# STM32G431xx register map
File version: 1.9
CPU: CM4 r0p1, little endian, MPU, FPU, 4 interrupt priority bits
Registers are 32-bit, read-write, reset 0x0 unless marked. A register's access mark holds for its fields unless they carry their own. Offsets are from the block's base; [hi:lo] are bit positions; {n}, {i} and the like mark numbered series.

## RCC (part 2 of 2) — Reset and clock control
Base 0x40021000
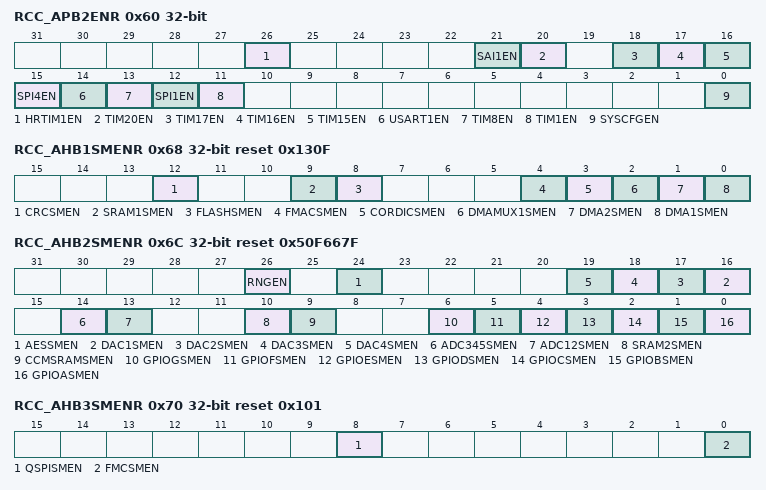
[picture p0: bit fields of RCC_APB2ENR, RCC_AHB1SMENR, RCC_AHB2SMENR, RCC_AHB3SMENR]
0x60 RCC_APB2ENR — APB2 peripheral clock enable register
  [26] HRTIM1EN — HRTIM1 clock enable Set and cleared by software.
    0=HRTIM1 clock disabled; 1=HRTIM1 clock enable
  [21] SAI1EN — SAI1 clock enable Set and cleared by software.
    0=SAI1 clock disabled; 1=SAI1 clock enabled
  [20] TIM20EN — TIM20 timer clock enable Set and cleared by software.
    0=TIM20 clock disabled; 1=TIM20 clock enabled
  [18] TIM17EN — TIM17 timer clock enable Set and cleared by software.
    0=TIM17 timer clock disabled; 1=TIM17 timer clock enabled
  [17] TIM16EN — TIM16 timer clock enable Set and cleared by software.
    0=TIM16 timer clock disabled; 1=TIM16 timer clock enabled
  [16] TIM15EN — TIM15 timer clock enable Set and cleared by software.
    0=TIM15 timer clock disabled; 1=TIM15 timer clock enabled
  [15] SPI4EN — SPI4 clock enable Set and cleared by software.
    0=SPI4 clock disabled; 1=SPI4 clock enabled
  [14] USART1EN — USART1clock enable Set and cleared by software.
    0=USART1clock disabled; 1=USART1clock enabled
  [13] TIM8EN — TIM8 timer clock enable Set and cleared by software.
    0=TIM8 timer clock disabled; 1=TIM8 timer clock enabled
  [12] SPI1EN — SPI1 clock enable Set and cleared by software.
    0=SPI1 clock disabled; 1=SPI1 clock enabled
  [11] TIM1EN — TIM1 timer clock enable Set and cleared by software.
    0=TIM1 timer clock disabled; 1=TIM1P timer clock enabled
  [0] SYSCFGEN — SYSCFG + COMP + VREFBUF + OPAMP clock enable Set and cleared by software.
    0=SYSCFG + COMP + VREFBUF + OPAMP clock disabled; 1=SYSCFG + COMP + VREFBUF + OPAMP clock enabled
0x68 RCC_AHB1SMENR reset 0x130F — AHB1 peripheral clocks enable in Sleep and Stop modes register
  [12] CRCSMEN — CRC clocks enable during Sleep and Stop modes Set and cleared by software.
    0=CRC clocks disabled by the clock gating during Sleep and Stop modes; 1=CRC clocks enabled by the clock gating<sup>(1)</sup> during Sleep and Stop modes
  [9] SRAM1SMEN — SRAM1 interface clocks enable during Sleep and Stop modes Set and cleared by software.
    0=SRAM1 interface clocks disabled by the clock gating<sup>(1)</sup> during Sleep and Stop modes; 1=SRAM1 interface clocks enabled by the clock gating<sup>(1)</sup> during Sleep and Stop modes
  [8] FLASHSMEN — Flash memory interface clocks enable during Sleep and Stop modes Set and cleared by software.
    0=Flash memory interface clocks disabled by the clock gating<sup>(1)</sup> during Sleep and Stop modes; 1=Flash memory interface clocks enabled by the clock gating<sup>(1)</sup> during Sleep and Stop modes
  [4] FMACSMEN — FMACSM clock enable. Set and cleared by software.
    0=FMACSM clocks disabled by the clock gating<sup>(1)</sup> during Sleep and Stop modes; 1=FMACSM clocks enabled by the clock gating<sup>(1)</sup> during Sleep and Stop modes
  [3] CORDICSMEN — CORDICSM clock enable. Set and cleared by software.
    0=CORDICSM clocks disabled; 1=CORDICSM clocks enabled
  [2] DMAMUX1SMEN — DMAMUX1 clock enable during Sleep and Stop modes. Set and cleared by software.
    0=DMAMUX1 clocks disabled by the clock gating<sup>(1)</sup> during Sleep and Stop modes; 1=DMAMUX1 clocks enabled by the clock gating<sup>(1)</sup> during Sleep and Stop modes
  [1] DMA2SMEN — DMA2 clocks enable during Sleep and Stop modes Set and cleared by software during Sleep mode.
    0=DMA2 clocks disabled by the clock gating<sup>(1)</sup> during Sleep and Stop modes; 1=DMA2 clocks enabled by the clock gating<sup>(1)</sup> during Sleep and Stop modes
  [0] DMA1SMEN — DMA1 clocks enable during Sleep and Stop modes Set and cleared by software.
    0=DMA1 clocks disabled by the clock gating<sup>(1)</sup> during Sleep and Stop modes; 1=DMA1 clocks enabled by the clock gating<sup>(1)</sup> during Sleep and Stop modes
0x6C RCC_AHB2SMENR reset 0x50F667F — AHB2 peripheral clocks enable in Sleep and Stop modes register
  [26] RNGEN — RNG enable Set and cleared by software.
    0=RNG disabled; 1=RNG enabled
  [24] AESSMEN — AESM clocks enable Set and cleared by software.
    0=AESM clocks disabled; 1=AESM clocks enabled
  [n+15] DAC{n}SMEN (n=1..4) — DAC{n} clock enable Set and cleared by software.
    0=DAC{n} clock disabled; 1=DAC{n} clock enabled during sleep and stop modes
  [14] ADC345SMEN — ADC345 clock enable Set and cleared by software.
    0=ADC345 clock disabled; 1=ADC345 clock enabled
  [13] ADC12SMEN — ADC12 clocks enable during Sleep and Stop modes Set and cleared by software.
    0=ADC12 clocks disabled by the clock gating during Sleep and Stop modes; 1=ADC12 clocks enabled by the clock gating<sup>(1)</sup> during Sleep and Stop modes
  [10] SRAM2SMEN — SRAM2 interface clocks enable during Sleep and Stop modes Set and cleared by software.
    0=SRAM2 interface clocks disabled by the clock gating<sup>(1)</sup> during Sleep and Stop modes; 1=SRAM2 interface clocks enabled by the clock gating<sup>(1)</sup> during Sleep and Stop modes
  [9] CCMSRAMSMEN — CCM SRAM interface clocks enable during Sleep and Stop modes Set and cleared by software.
    0=CCM SRAM interface clocks disabled by the clock gating<sup>(1)</sup> during Sleep and Stop modes; 1=CCM SRAM interface clocks enabled by the clock gating<sup>(1)</sup> during Sleep and Stop modes
  [6] GPIOGSMEN — IO port G clocks enable during Sleep and Stop modes Set and cleared by software.
    0=IO port G clocks disabled by the clock gating<sup>(1)</sup> during Sleep and Stop modes; 1=IO port G clocks enabled by the clock gating<sup>(1)</sup> during Sleep and Stop modes
  [5] GPIOFSMEN — IO port F clocks enable during Sleep and Stop modes Set and cleared by software.
    0=IO port F clocks disabled by the clock gating<sup>(1)</sup> during Sleep and Stop modes; 1=IO port F clocks enabled by the clock gating<sup>(1)</sup> during Sleep and Stop modes
  [4] GPIOESMEN — IO port E clocks enable during Sleep and Stop modes Set and cleared by software.
    0=IO port E clocks disabled by the clock gating<sup>(1)</sup> during Sleep and Stop modes; 1=IO port E clocks enabled by the clock gating<sup>(1)</sup> during Sleep and Stop modes
  [3] GPIODSMEN — IO port D clocks enable during Sleep and Stop modes Set and cleared by software.
    0=IO port D clocks disabled by the clock gating<sup>(1)</sup> during Sleep and Stop modes; 1=IO port D clocks enabled by the clock gating<sup>(1)</sup> during Sleep and Stop modes
  [2] GPIOCSMEN — IO port C clocks enable during Sleep and Stop modes Set and cleared by software.
    0=IO port C clocks disabled by the clock gating<sup>(1)</sup> during Sleep and Stop modes; 1=IO port C clocks enabled by the clock gating<sup>(1)</sup> during Sleep and Stop modes
  [1] GPIOBSMEN — IO port B clocks enable during Sleep and Stop modes Set and cleared by software.
    0=IO port B clocks disabled by the clock gating<sup>(1)</sup> during Sleep and Stop modes; 1=IO port B clocks enabled by the clock gating<sup>(1)</sup> during Sleep and Stop modes
  [0] GPIOASMEN — IO port A clocks enable during Sleep and Stop modes Set and cleared by software.
    0=IO port A clocks disabled by the clock gating<sup>(1)</sup> during Sleep and Stop modes; 1=IO port A clocks enabled by the clock gating<sup>(1)</sup> during Sleep and Stop modes
0x70 RCC_AHB3SMENR reset 0x101 — AHB3 peripheral clocks enable in Sleep and Stop modes register
  [8] QSPISMEN — QUADSPI memory interface clock enable during Sleep and Stop modes Set and cleared by software.
    0=QUADSPI clock disabled by the clock gating during Sleep and Stop modes; 1=QUADSPI clock enabled by the clock gating<sup>(1)</sup> during Sleep and Stop modes
  [0] FMCSMEN — Flexible static memory controller clocks enable during Sleep and Stop modes Set and cleared by software.
    0=FSMC clocks disabled by the clock gating<sup>(1)</sup> during Sleep and Stop modes; 1=FSMC clocks enabled by the clock gating<sup>(1)</sup> during Sleep and Stop modes
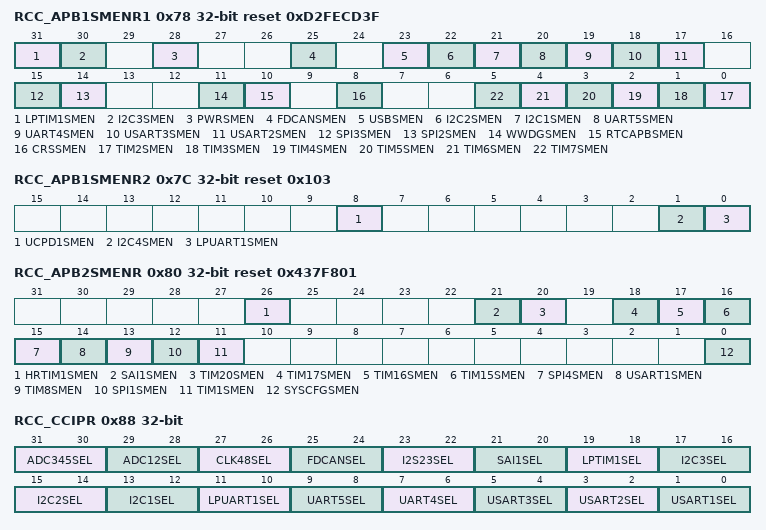
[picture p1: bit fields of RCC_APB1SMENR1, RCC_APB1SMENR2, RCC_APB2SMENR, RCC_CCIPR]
0x78 RCC_APB1SMENR1 reset 0xD2FECD3F — APB1 peripheral clocks enable in Sleep and Stop modes register 1
  [31] LPTIM1SMEN — Low power timer 1 clocks enable during Sleep and Stop modes Set and cleared by software.
    0=LPTIM1 clocks disabled by the clock gating during Sleep and Stop modes; 1=LPTIM1 clocks enabled by the clock gating<sup>(1)</sup> during Sleep and Stop modes
  [30] I2C3SMEN — I2C3 clocks enable during Sleep and Stop modes Set and cleared by software.
    0=I2C3 clocks disabled by the clock gating<sup>(1)</sup> during Sleep and Stop modes; 1=I2C3 clocks enabled by the clock gating<sup>(1)</sup> during Sleep and Stop modes
  [28] PWRSMEN — Power interface clocks enable during Sleep and Stop modes Set and cleared by software.
    0=Power interface clocks disabled by the clock gating<sup>(1)</sup> during Sleep and Stop modes; 1=Power interface clocks enabled by the clock gating<sup>(1)</sup> during Sleep and Stop modes
  [25] FDCANSMEN — FDCAN clocks enable during Sleep and Stop modes Set and cleared by software.
    0=FDCAN clocks disabled by the clock gating<sup>(1)</sup> during Sleep and Stop modes; 1=FDCAN clocks enabled by the clock gating<sup>(1)</sup> during Sleep and Stop modes
  [23] USBSMEN — USB device clocks enable during Sleep and Stop modes Set and cleared by software.
    0=USB device clocks disabled by the clock gating<sup>(1)</sup> during Sleep and Stop modes; 1=USB device clocks enabled by the clock gating<sup>(1)</sup> during Sleep and Stop modes
  [22] I2C2SMEN — I2C2 clocks enable during Sleep and Stop modes Set and cleared by software.
    0=I2C2 clocks disabled by the clock gating<sup>(1)</sup> during Sleep and Stop modes; 1=I2C2 clocks enabled by the clock gating<sup>(1)</sup> during Sleep and Stop modes
  [21] I2C1SMEN — I2C1 clocks enable during Sleep and Stop modes Set and cleared by software.
    0=I2C1 clocks disabled by the clock gating<sup>(1)</sup> during Sleep and Stop modes; 1=I2C1 clocks enabled by the clock gating<sup>(1)</sup> during Sleep and Stop modes
  [20] UART5SMEN — UART5 clocks enable during Sleep and Stop modes Set and cleared by software.
    0=UART5 clocks disabled by the clock gating<sup>(1)</sup> during Sleep and Stop modes; 1=UART5 clocks enabled by the clock gating<sup>(1)</sup> during Sleep and Stop modes
  [19] UART4SMEN — UART4 clocks enable during Sleep and Stop modes Set and cleared by software.
    0=UART4 clocks disabled by the clock gating<sup>(1)</sup> during Sleep and Stop modes; 1=UART4 clocks enabled by the clock gating<sup>(1)</sup> during Sleep and Stop modes
  [18] USART3SMEN — USART3 clocks enable during Sleep and Stop modes Set and cleared by software.
    0=USART3 clocks disabled by the clock gating<sup>(1)</sup> during Sleep and Stop modes; 1=USART3 clocks enabled by the clock gating<sup>(1)</sup> during Sleep and Stop modes
  [17] USART2SMEN — USART2 clocks enable during Sleep and Stop modes Set and cleared by software.
    0=USART2 clocks disabled by the clock gating<sup>(1)</sup> during Sleep and Stop modes; 1=USART2 clocks enabled by the clock gating<sup>(1)</sup> during Sleep and Stop modes
  [15] SPI3SMEN — SPI3 clocks enable during Sleep and Stop modes Set and cleared by software.
    0=SPI3 clocks disabled by the clock gating<sup>(1)</sup> during Sleep and Stop modes; 1=SPI3 clocks enabled by the clock gating<sup>(1)</sup> during Sleep and Stop modes
  [14] SPI2SMEN — SPI2 clocks enable during Sleep and Stop modes Set and cleared by software.
    0=SPI2 clocks disabled by the clock gating<sup>(1)</sup> during Sleep and Stop modes; 1=SPI2 clocks enabled by the clock gating<sup>(1)</sup> during Sleep and Stop modes
  [11] WWDGSMEN — Window watchdog clocks enable during Sleep and Stop modes Set and cleared by software. This bit is forced to ‘1’ by hardware when the hardware WWDG option is activated.
    0=Window watchdog clocks disabled by the clock gating<sup>(1)</sup> during Sleep and Stop modes; 1=Window watchdog clocks enabled by the clock gating<sup>(1)</sup> during Sleep and Stop modes
  [10] RTCAPBSMEN — RTC APB clock enable during Sleep and Stop modes Set and cleared by software
    0=RTC APB clock disabled by the clock gating<sup>(1)</sup> during Sleep and Stop modes; 1=RTC APB clock enabled by the clock gating<sup>(1)</sup> during Sleep and Stop modes
  [8] CRSSMEN — CRS timer clocks enable during Sleep and Stop modes Set and cleared by software.
    0=CRS clocks disabled by the clock gating<sup>(1)</sup> during Sleep and Stop modes; 1=CRS clocks enabled by the clock gating<sup>(1)</sup> during Sleep and Stop modes
  [n-2] TIM{n}SMEN (n=2..7) — TIM{n} timer clocks enable during Sleep and Stop modes Set and cleared by software.
    0=TIM{n} clocks disabled by the clock gating<sup>(1)</sup> during Sleep and Stop modes; 1=TIM{n} clocks enabled by the clock gating<sup>(1)</sup> during Sleep and Stop modes
0x7C RCC_APB1SMENR2 reset 0x103 — APB1 peripheral clocks enable in Sleep and Stop modes register 2
  [8] UCPD1SMEN — UCPD1 clocks enable during Sleep and Stop modes Set and cleared by software.
    0=UCPD1 clocks disabled by the clock gating during Sleep and Stop modes; 1=UCPD1 clocks enabled by the clock gating<sup>(1)</sup> during Sleep and Stop modes
  [1] I2C4SMEN — I2C4 clocks enable during Sleep and Stop modes Set and cleared by software
    0=I2C4 clocks disabled by the clock gating during Sleep and Stop modes; 1=I2C4 clock enabled by the clock gating<sup>(1)</sup> during Sleep and Stop modes
  [0] LPUART1SMEN — Low power UART 1 clocks enable during Sleep and Stop modes Set and cleared by software.
    0=LPUART1 clocks disabled by the clock gating<sup>(1)</sup> during Sleep and Stop modes; 1=LPUART1 clocks enabled by the clock gating<sup>(1)</sup> during Sleep and Stop modes
0x80 RCC_APB2SMENR reset 0x437F801 — APB2 peripheral clocks enable in Sleep and Stop modes register
  [26] HRTIM1SMEN — HRTIM1 timer clocks enable during Sleep and Stop modes Set and cleared by software.
    0=HRTIM1 clocks disabled by the clock gating<sup>(1)</sup> during Sleep and Stop modes; 1=HRTIM1 clocks enabled by the clock gating<sup>(1)</sup> during Sleep and Stop modes
  [21] SAI1SMEN — SAI1 clocks enable during Sleep and Stop modes Set and cleared by software.
    0=SAI1 clocks disabled by the clock gating<sup>(1)</sup> during Sleep and Stop modes; 1=SAI1 clocks enabled by the clock gating<sup>(1)</sup> during Sleep and Stop modes
  [20] TIM20SMEN — TIM20 timer clocks enable during Sleep and Stop modes Set and cleared by software.
    0=TIM20 clocks disabled by the clock gating<sup>(1)</sup> during Sleep and Stop modes; 1=TIM20 clocks enabled by the clock gating<sup>(1)</sup> during Sleep and Stop modes
  [18] TIM17SMEN — TIM17 timer clocks enable during Sleep and Stop modes Set and cleared by software.
    0=TIM17 timer clocks disabled by the clock gating<sup>(1)</sup> during Sleep and Stop modes; 1=TIM17 timer clocks enabled by the clock gating<sup>(1)</sup> during Sleep and Stop modes
  [17] TIM16SMEN — TIM16 timer clocks enable during Sleep and Stop modes Set and cleared by software.
    0=TIM16 timer clocks disabled by the clock gating during Sleep and Stop modes; 1=TIM16 timer clocks enabled by the clock gating<sup>(1)</sup> during Sleep and Stop modes
  [16] TIM15SMEN — TIM15 timer clocks enable during Sleep and Stop modes Set and cleared by software.
    0=TIM15 timer clocks disabled by the clock gating<sup>(1)</sup> during Sleep and Stop modes; 1=TIM15 timer clocks enabled by the clock gating<sup>(1)</sup> during Sleep and Stop mode
  [15] SPI4SMEN — SPI4 timer clocks enable during Sleep and Stop modes Set and cleared by software.
    0=SPI4 clocks disabled by the clock gating<sup>(1)</sup> during Sleep and Stop modes; 1=SPI4 clocks enabled by the clock gating<sup>(1)</sup> during Sleep and Stop mode
  [14] USART1SMEN — USART1clocks enable during Sleep and Stop modes Set and cleared by software.
    0=USART1clocks disabled by the clock gating<sup>(1)</sup> during Sleep and Stop modes; 1=USART1clocks enabled by the clock gating<sup>(1)</sup> during Sleep and Stop modes
  [13] TIM8SMEN — TIM8 timer clocks enable during Sleep and Stop modes Set and cleared by software.
    0=TIM8 timer clocks disabled by the clock gating<sup>(1)</sup> during Sleep and Stop modes; 1=TIM8 timer clocks enabled by the clock gating<sup>(1)</sup> during Sleep and Stop modes
  [12] SPI1SMEN — SPI1 clocks enable during Sleep and Stop modes Set and cleared by software.
    0=SPI1 clocks disabled by the clock gating during<sup>(1)</sup> Sleep and Stop modes; 1=SPI1 clocks enabled by the clock gating during<sup>(1)</sup> Sleep and Stop modes
  [11] TIM1SMEN — TIM1 timer clocks enable during Sleep and Stop modes Set and cleared by software.
    0=TIM1 timer clocks disabled by the clock gating<sup>(1)</sup> during Sleep and Stop modes; 1=TIM1P timer clocks enabled by the clock gating<sup>(1)</sup> during Sleep and Stop modes
  [0] SYSCFGSMEN — SYSCFG + COMP + VREFBUF + OPAMP clocks enable during Sleep and Stop modes Set and cleared by software.
    0=SYSCFG + COMP + VREFBUF + OPAMP clocks disabled by the clock gating<sup>(1)</sup> during Sleep and Stop modes; 1=SYSCFG + COMP + VREFBUF + OPAMP clocks enabled by the clock gating<sup>(1)</sup> during Sleep and Stop modes
0x88 RCC_CCIPR — Peripherals independent clock configuration register
  [31:30] ADC345SEL — ADC3/4/5 clock source selection These bits are set and cleared by software to select the clock source used by the ADC345 interface.
    0=No clock selected; 1=PLL “P” clock selected as ADC345 clock; 2=System clock selected as ADC3/4/5 clock
  [29:28] ADC12SEL — ADC1/2 clock source selection These bits are set and cleared by software to select the clock source used by the ADC interface.
    0=No clock selected; 1=PLL “P” clock selected as ADC1/2 clock; 2=System clock selected as ADC1/2 clock
  [27:26] CLK48SEL — 48 MHz clock source selection These bits are set and cleared by software to select the 48 MHz clock source used by USB device FS and RNG.
    0=HSI48 clock selected as 48 MHz clock; 2=PLL “Q” clock (PLL48M1CLK) selected as 48 MHz clock; 3=Reserved, must be kept at reset value
  [25:24] FDCANSEL
  [23:22] I2S23SEL — clock source selection These bits are set and cleared by software to select the I2S23 clock source.
    0=System clock selected as I2S23 clock; 1=PLL “Q” clock selected as I2S23 clock; 2=Clock provided on I2S_CKIN pin is selected as I2S23 clock; 3=HSI16 clock selected as I2S23 clock
  [21:20] SAI1SEL — clock source selection These bits are set and cleared by software to select the SAI clock source.
    0=System clock selected as SAI clock; 1=PLL “Q” clock selected as SAI clock; 2=Clock provided on I2S_CKIN pin selected as SAI clock; 3=HSI16 clock selected as SAI clock
  [19:18] LPTIM1SEL — Low power timer 1 clock source selection These bits are set and cleared by software to select the LPTIM1 clock source.
    0=PCLK selected as LPTIM1 clock; 1=LSI clock selected as LPTIM1 clock; 2=HSI16 clock selected as LPTIM1 clock; 3=LSE clock selected as LPTIM1 clock
  [17:16] I2C3SEL — I2C3 clock source selection These bits are set and cleared by software to select the I2C3 clock source.
    0=PCLK selected as I2C3 clock; 1=System clock (SYSCLK) selected as I2C3 clock; 2=HSI16 clock selected as I2C3 clock
  [15:14] I2C2SEL — I2C2 clock source selection These bits are set and cleared by software to select the I2C2 clock source.
    0=PCLK selected as I2C2 clock; 1=System clock (SYSCLK) selected as I2C2 clock; 2=HSI16 clock selected as I2C2 clock
  [13:12] I2C1SEL — I2C1 clock source selection These bits are set and cleared by software to select the I2C1 clock source.
    0=PCLK selected as I2C1 clock; 1=System clock (SYSCLK) selected as I2C1 clock; 2=HSI16 clock selected as I2C1 clock
  [11:10] LPUART1SEL — LPUART1 clock source selection These bits are set and cleared by software to select the LPUART1 clock source.
    0=PCLK selected as LPUART1 clock; 1=System clock (SYSCLK) selected as LPUART1 clock; 2=HSI16 clock selected as LPUART1 clock; 3=LSE clock selected as LPUART1 clock
  [9:8] UART5SEL — UART5 clock source selection These bits are set and cleared by software to select the UART5 clock source.
    0=PCLK selected as UART5 clock; 1=System clock (SYSCLK) selected as UART5 clock; 2=HSI16 clock selected as UART5 clock; 3=LSE clock selected as UART5 clock
  [7:6] UART4SEL — UART4 clock source selection This bit is set and cleared by software to select the UART4 clock source.
    0=PCLK selected as UART4 clock; 1=System clock (SYSCLK) selected as UART4 clock; 2=HSI16 clock selected as UART4 clock; 3=LSE clock selected as UART4 clock
  [5:4] USART3SEL — USART3 clock source selection This bit is set and cleared by software to select the USART3 clock source.
    0=PCLK selected as USART3 clock; 1=System clock (SYSCLK) selected as USART3 clock; 2=HSI16 clock selected as USART3 clock; 3=LSE clock selected as USART3 clock
  [3:2] USART2SEL — USART2 clock source selection This bit is set and cleared by software to select the USART2 clock source.
    0=PCLK selected as USART2 clock; 1=System clock (SYSCLK) selected as USART2 clock; 2=HSI16 clock selected as USART2 clock; 3=LSE clock selected as USART2 clock
  [1:0] USART1SEL — USART1 clock source selection This bit is set and cleared by software to select the USART1 clock source.
    0=PCLK selected as USART1 clock; 1=System clock (SYSCLK) selected as USART1 clock; 2=HSI16 clock selected as USART1 clock; 3=LSE clock selected as USART1 clock
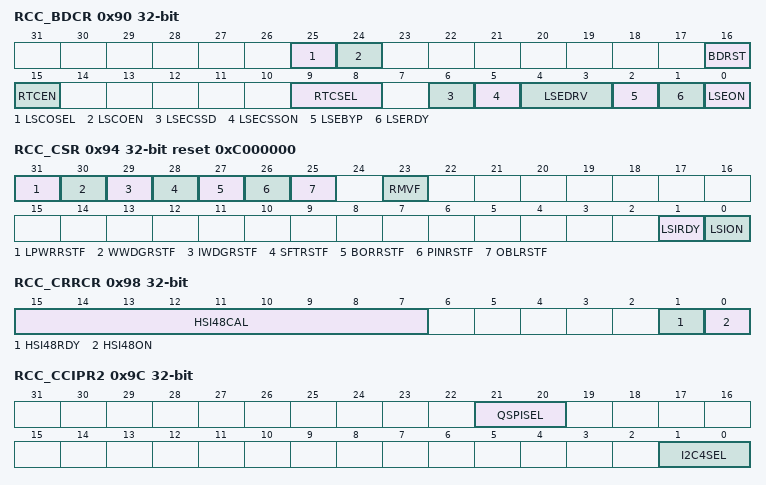
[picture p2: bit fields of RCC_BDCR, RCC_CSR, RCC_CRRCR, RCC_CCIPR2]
0x90 RCC_BDCR access per field — RTC domain control register
  [25] LSCOSEL rw — Low speed clock output selection Set and cleared by software.
    0=LSI clock selected; 1=LSE clock selected
  [24] LSCOEN rw — Low speed clock output enable Set and cleared by software.
    0=Low speed clock output (LSCO) disable; 1=Low speed clock output (LSCO) enable
  [16] BDRST rw — RTC domain software reset Set and cleared by software.
    0=Reset not activated; 1=Reset the entire RTC domain
  [15] RTCEN rw — RTC clock enable Set and cleared by software.
    0=RTC clock disabled; 1=RTC clock enabled
  [9:8] RTCSEL rw — RTC clock source selection Set by software to select the clock source for the RTC. Once the RTC clock source has been selected, it cannot be changed anymore unless the RTC domain is reset, or unless a failure is detected on LSE (LSECSSD is set). The BDRST bit can be used to reset them.
    0=No clock; 1=LSE oscillator clock used as RTC clock; 2=LSI oscillator clock used as RTC clock; 3=HSE oscillator clock divided by 32 used as RTC clock
  [6] LSECSSD ro — CSS on LSE failure Detection Set by hardware to indicate when a failure has been detected by the Clock Security System on the external 32 kHz oscillator (LSE).
    0=No failure detected on LSE (32 kHz oscillator); 1=Failure detected on LSE (32 kHz oscillator)
  [5] LSECSSON rw — CSS on LSE enable Set by software to enable the Clock Security System on LSE (32 kHz oscillator). LSECSSON must be enabled after the LSE oscillator is enabled (LSEON bit enabled) and ready (LSERDY flag set by hardware), and after the RTCSEL bit is selected. Once enabled this bit cannot be disabled, except after a LSE failure detection (LSECSSD =1). In that case the software MUST disable the LSECSSON bit.
    0=CSS on LSE (32 kHz external oscillator) OFF; 1=CSS on LSE (32 kHz external oscillator) ON
  [4:3] LSEDRV rw — LSE oscillator drive capability Set by software to modulate the LSE oscillator’s drive capability. The oscillator is in Xtal mode when it is not in bypass mode.
    0=‘Xtal mode’ lower driving capability; 1=‘Xtal mode’ medium low driving capability; 2=‘Xtal mode’ medium high driving capability; 3=‘Xtal mode’ higher driving capability
  [2] LSEBYP rw — LSE oscillator bypass Set and cleared by software to bypass oscillator in debug mode. This bit can be written only when the external 32 kHz oscillator is disabled (LSEON=0 and LSERDY=0).
    0=LSE oscillator not bypassed; 1=LSE oscillator bypassed
  [1] LSERDY ro — LSE oscillator ready Set and cleared by hardware to indicate when the external 32 kHz oscillator is stable. After the LSEON bit is cleared, LSERDY goes low after 6 external low-speed oscillator clock cycles.
    0=LSE oscillator not ready; 1=LSE oscillator ready
  [0] LSEON rw — LSE oscillator enable Set and cleared by software.
    0=LSE oscillator OFF; 1=LSE oscillator ON
0x94 RCC_CSR access per field reset 0xC000000 — Control/status register
  [31] LPWRRSTF ro — Low-power reset flag Set by hardware when a reset occurs due to illegal Stop, Standby or Shutdown mode entry. Cleared by writing to the RMVF bit.
    0=No illegal mode reset occurred; 1=Illegal mode reset occurred
  [30] WWDGRSTF ro — Window watchdog reset flag Set by hardware when a window watchdog reset occurs. Cleared by writing to the RMVF bit.
    0=No window watchdog reset occurred; 1=Window watchdog reset occurred
  [29] IWDGRSTF ro — Independent window watchdog reset flag Set by hardware when an independent watchdog reset domain occurs. Cleared by writing to the RMVF bit.
    0=No independent watchdog reset occurred; 1=Independent watchdog reset occurred
  [28] SFTRSTF ro — Software reset flag Set by hardware when a software reset occurs. Cleared by writing to the RMVF bit.
    0=No software reset occurred; 1=Software reset occurred
  [27] BORRSTF ro — BOR flag Set by hardware when a BOR occurs. Cleared by writing to the RMVF bit.
    0=No BOR occurred; 1=BOR occurred
  [26] PINRSTF ro — Pin reset flag Set by hardware when a reset from the NRST pin occurs. Cleared by writing to the RMVF bit.
    0=No reset from NRST pin occurred; 1=Reset from NRST pin occurred
  [25] OBLRSTF ro — Option byte loader reset flag Set by hardware when a reset from the Option Byte loading occurs. Cleared by writing to the RMVF bit.
    0=No reset from Option Byte loading occurred; 1=Reset from Option Byte loading occurred
  [23] RMVF rw — Remove reset flag Set by software to clear the reset flags.
    0=No effect; 1=Clear the reset flags
  [1] LSIRDY ro — LSI oscillator ready Set and cleared by hardware to indicate when the LSI oscillator is stable. After the LSION bit is cleared, LSIRDY goes low after 3 LSI oscillator clock cycles. This bit can be set even if LSION = 0 if the LSI is requested by the Clock Security System on LSE, by the Independent Watchdog or by the RTC.
    0=LSI oscillator not ready; 1=LSI oscillator ready
  [0] LSION rw — LSI oscillator enable Set and cleared by software.
    0=LSI oscillator OFF; 1=LSI oscillator ON
0x98 RCC_CRRCR access per field — Clock recovery RC register
  [15:7] HSI48CAL ro — HSI48 clock calibration These bits are initialized at startup with the factory-programmed HSI48 calibration trim value. They are ready only.
  [1] HSI48RDY ro — HSI48 clock ready flag Set by hardware to indicate that HSI48 oscillator is stable. This bit is set only when HSI48 is enabled by software by setting HSI48ON.
    0=HSI48 oscillator not ready; 1=HSI48 oscillator ready
  [0] HSI48ON rw — HSI48 clock enable Set and cleared by software. Cleared by hardware to stop the HSI48 when entering in Stop, Standby or Shutdown modes.
    0=HSI48 oscillator OFF; 1=HSI48 oscillator ON
0x9C RCC_CCIPR2 — Peripherals independent clock configuration register
  [21:20] QSPISEL — QUADSPI clock source selection Set and reset by software.
    0=system clock selected as QUADSPI kernel clock; 1=HSI16 clock selected as QUADSPI kernel clock; 2=PLL “Q” clock selected as QUADSPI kernel clock
  [1:0] I2C4SEL — I2C4 clock source selection These bits are set and cleared by software to select the I2C4 clock source.
    0=PCLK selected as I2C4 clock; 1=System clock (SYSCLK) selected as I2C4 clock; 2=HSI16 clock selected as I2C4 clock
